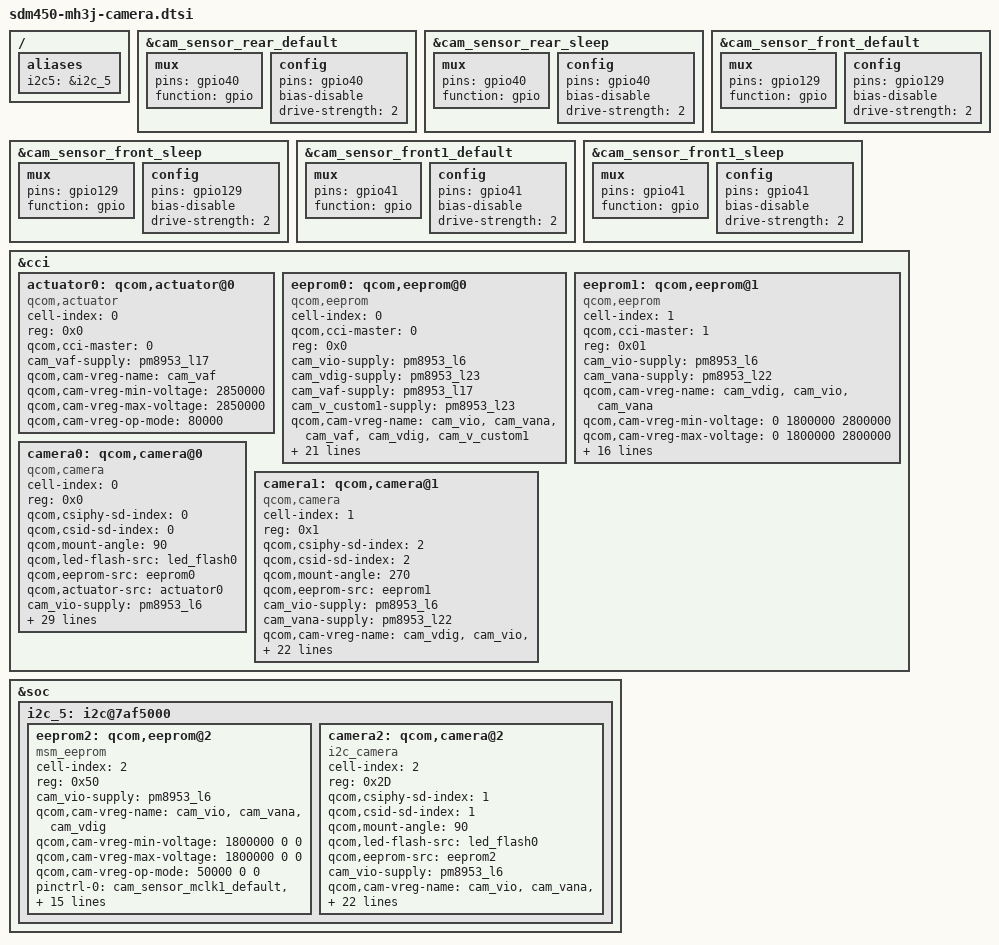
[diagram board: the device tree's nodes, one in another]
/*
 * Copyright (c) 2018, The Linux Foundation. All rights reserved.
 *
 * This program is free software; you can redistribute it and/or modify
 * it under the terms of the GNU General Public License version 2 and
 * only version 2 as published by the Free Software Foundation.
 *
 * This program is distributed in the hope that it will be useful,
 * but WITHOUT ANY WARRANTY; without even the implied warranty of
 * MERCHANTABILITY or FITNESS FOR A PARTICULAR PURPOSE.  See the
 * GNU General Public License for more details.
 */

#include "../sdm450-mh3j_common/sdm450-mh3j_common-camera.dtsi"
//#include "../../../qcom/msm8953-camera-sensor-mtp.dtsi"

/* PIN settings */
&cam_sensor_rear_default{
	/* RESET */
	mux {
		pins = "gpio40";
		function = "gpio";
	};

	config {
		pins = "gpio40";
		bias-disable; /* No PULL */
		drive-strength = <2>; /* 2 MA */
	};
};

&cam_sensor_rear_sleep{
	/* RESET */
	mux {
		pins = "gpio40";
		function = "gpio";
	};

	config {
		pins = "gpio40";
		bias-disable; /* No PULL */
		drive-strength = <2>; /* 2 MA */
	};
};

&cam_sensor_front_default{
	/* RESET */
	mux {
		pins = "gpio129";
		function = "gpio";
	};

	config {
		pins = "gpio129";
		bias-disable; /* No PULL */
		drive-strength = <2>; /* 2 MA */
	};
};

&cam_sensor_front_sleep{
	/* RESET */
	mux {
		pins = "gpio129";
		function = "gpio";
	};

	config {
		pins = "gpio129";
		bias-disable; /* No PULL */
		drive-strength = <2>; /* 2 MA */
	};
};

&cam_sensor_front1_default{
	/* RESET */
	mux {
		pins = "gpio41";
		function = "gpio";
	};

	config {
		pins = "gpio41";
		bias-disable; /* No PULL */
		drive-strength = <2>; /* 2 MA */
	};
};

&cam_sensor_front1_sleep{
	/* RESET */
	mux {
		pins = "gpio41";
		function = "gpio";
	};

	config {
		pins = "gpio41";
		bias-disable; /* No PULL */
		drive-strength = <2>; /* 2 MA */
	};
};

&cci {
	actuator0: qcom,actuator@0 {
		cell-index = <0>;
		reg = <0x0>;
		compatible = "qcom,actuator";
		qcom,cci-master = <0>;
		cam_vaf-supply = <&pm8953_l17>;
		qcom,cam-vreg-name = "cam_vaf";
		qcom,cam-vreg-min-voltage = <2850000>;
		qcom,cam-vreg-max-voltage = <2850000>;
		qcom,cam-vreg-op-mode = <80000>;
	};

	eeprom0: qcom,eeprom@0 {
		cell-index = <0>;
		compatible = "qcom,eeprom";
		qcom,cci-master = <0>;
		reg = <0x0>;
		cam_vio-supply = <&pm8953_l6>;
		cam_vdig-supply = <&pm8953_l23>;
		cam_vaf-supply = <&pm8953_l17>;
		cam_v_custom1-supply = <&pm8953_l23>;
		qcom,cam-vreg-name = "cam_vio", "cam_vana", "cam_vaf",
						"cam_vdig", "cam_v_custom1";
		qcom,cam-vreg-min-voltage = <1800000 0 2850000 1200000 1200000>;
		qcom,cam-vreg-max-voltage = <1800000 0 2850000 1200000 1200000>;
		qcom,cam-vreg-op-mode = <50000 0 100000 200000 200000>;
		pinctrl-names = "cam_default", "cam_suspend";
		pinctrl-0 = <&cam_sensor_mclk0_default
				&cam_sensor_rear_default>;
		pinctrl-1 = <&cam_sensor_mclk0_sleep &cam_sensor_rear_sleep>;
		gpios = <&tlmm 26 0>,
			<&tlmm 40 0>,
			<&tlmm 39 0>;

		qcom,gpio-no-mux = <0>;
		qcom,gpio-reset = <1>;
		qcom,gpio-vana = <2>;

		qcom,gpio-req-tbl-num = <0 1 2>;
		qcom,gpio-req-tbl-flags = <1 0 0>;
		qcom,gpio-req-tbl-label = "CAMIF_MCLK0",
			"CAM_RESET0",
			"CAM_AVDD";

		status = "ok";
		clocks = <&clock_gcc clk_mclk0_clk_src>,
				<&clock_gcc clk_gcc_camss_mclk0_clk>;
		clock-names = "cam_src_clk", "cam_clk";
		qcom,clock-rates = <24000000 0>;
	};

	eeprom1: qcom,eeprom@1 {
		cell-index = <1>;
		compatible = "qcom,eeprom";
		qcom,cci-master = <1>;
		reg = <0x01>;
		cam_vio-supply = <&pm8953_l6>;
		cam_vana-supply = <&pm8953_l22>;
		qcom,cam-vreg-name = "cam_vdig", "cam_vio", "cam_vana";

		qcom,cam-vreg-min-voltage = <0 1800000 2800000>;
		qcom,cam-vreg-max-voltage = <0 1800000 2800000>;
		qcom,cam-vreg-op-mode = <0 50000 42000>;

		pinctrl-names = "cam_default", "cam_suspend";
		pinctrl-0 = <&cam_sensor_mclk2_default
				&cam_sensor_front_default>;
		pinctrl-1 = <&cam_sensor_mclk2_sleep
				&cam_sensor_front_sleep>;
		gpios = <&tlmm 28 0>,
	               <&tlmm 129 0>,
		        <&tlmm 131 0>;

		qcom,gpio-no-mux = <0>;
		qcom,gpio-reset = <1>;
		qcom,gpio-vdig = <2>;
		qcom,gpio-req-tbl-num = <0 1 2>;
		qcom,gpio-req-tbl-flags = <1 0 0>;
		qcom,gpio-req-tbl-label = "CAMIF_MCLK2",
					  "CAM_RESET2",
					  "CAM_DVDD";

		status = "ok";
		clocks = <&clock_gcc clk_mclk2_clk_src>,
				<&clock_gcc clk_gcc_camss_mclk2_clk>;
		clock-names = "cam_src_clk", "cam_clk";
		qcom,clock-rates = <24000000 0>;

	};

	camera0: qcom,camera@0 {
		cell-index = <0>;
		compatible = "qcom,camera";
		reg = <0x0>;
		qcom,csiphy-sd-index = <0>;
		qcom,csid-sd-index = <0>;
		qcom,mount-angle = <90>;
		qcom,led-flash-src = <&led_flash0>;
		qcom,eeprom-src = <&eeprom0>;
		qcom,actuator-src = <&actuator0>;
		cam_vio-supply = <&pm8953_l6>;
		cam_vdig-supply = <&pm8953_l23>;
		cam_vaf-supply = <&pm8953_l17>;
		cam_v_custom1-supply = <&pm8953_l23>;
		qcom,cam-vreg-name = "cam_vio", "cam_vana", "cam_vaf",
						"cam_vdig", "cam_v_custom1";
		qcom,cam-vreg-min-voltage = <1800000 0 2850000 1200000 1200000>;
		qcom,cam-vreg-max-voltage = <1800000 0 2850000 1200000 1200000>;
		qcom,cam-vreg-op-mode = <50000 0 100000 200000 200000>;
		pinctrl-names = "cam_default", "cam_suspend";
		pinctrl-0 = <&cam_sensor_mclk0_default
				&cam_sensor_rear_default>;
		pinctrl-1 = <&cam_sensor_mclk0_sleep &cam_sensor_rear_sleep>;
		gpios = <&tlmm 26 0>,
			<&tlmm 40 0>,
			<&tlmm 39 0>;

		qcom,gpio-no-mux = <0>;
		qcom,gpio-reset = <1>;
		qcom,gpio-vana = <2>;

		qcom,gpio-req-tbl-num = <0 1 2>;
		qcom,gpio-req-tbl-flags = <1 0 0>;
		qcom,gpio-req-tbl-label = "CAMIF_MCLK0",
			"CAM_RESET0",
			"CAM_AVDD";

		qcom,sensor-position = <0>;
		qcom,sensor-mode = <0>;
		qcom,cci-master = <0>;
		status = "ok";
		clocks = <&clock_gcc clk_mclk0_clk_src>,
				<&clock_gcc clk_gcc_camss_mclk0_clk>;
		clock-names = "cam_src_clk", "cam_clk";
		qcom,clock-rates = <24000000 0>;
	};

	camera1: qcom,camera@1 {
		cell-index = <1>;
		compatible = "qcom,camera";
		reg = <0x1>;
		qcom,csiphy-sd-index = <2>;
		qcom,csid-sd-index = <2>;
		qcom,mount-angle = <270>;
		qcom,eeprom-src = <&eeprom1>;
		cam_vio-supply = <&pm8953_l6>;
		cam_vana-supply = <&pm8953_l22>;
		qcom,cam-vreg-name = "cam_vdig", "cam_vio", "cam_vana";

		qcom,cam-vreg-min-voltage = <0 1800000 2800000>;
		qcom,cam-vreg-max-voltage = <0 1800000 2800000>;
		qcom,cam-vreg-op-mode = <0 50000 42000>;

		pinctrl-names = "cam_default", "cam_suspend";
		pinctrl-0 = <&cam_sensor_mclk2_default
				&cam_sensor_front_default>;
		pinctrl-1 = <&cam_sensor_mclk2_sleep
				&cam_sensor_front_sleep>;
		gpios = <&tlmm 28 0>,
	               <&tlmm 129 0>,
		        <&tlmm 131 0>;

		qcom,gpio-no-mux = <0>;
		qcom,gpio-reset = <1>;
		qcom,gpio-vdig = <2>;
		qcom,gpio-req-tbl-num = <0 1 2>;
		qcom,gpio-req-tbl-flags = <1 0 0>;
		qcom,gpio-req-tbl-label = "CAMIF_MCLK2",
					  "CAM_RESET2",
					  "CAM_DVDD";

		qcom,sensor-position = <1>;
		qcom,sensor-mode = <0>;
		qcom,cci-master = <1>;
		status = "ok";
		clocks = <&clock_gcc clk_mclk2_clk_src>,
			<&clock_gcc clk_gcc_camss_mclk2_clk>;
		clock-names = "cam_src_clk", "cam_clk";
		qcom,clock-rates = <24000000 0>;
	};
};

/*W13M Rear Camera*/
/{
	aliases {
		i2c5 = &i2c_5;
	};
};

&soc{
	i2c_5: i2c@7af5000 { /* BLSP2 QUP1 */
		status = "okay";
	};
};

&i2c_5 {
	eeprom2: qcom,eeprom@2 {
		cell-index = <2>;
		compatible = "msm_eeprom";
		reg = <0x50>;
		cam_vio-supply = <&pm8953_l6>;
		qcom,cam-vreg-name = "cam_vio", "cam_vana", "cam_vdig";
		qcom,cam-vreg-min-voltage = <1800000 0 0>;
		qcom,cam-vreg-max-voltage = <1800000 0 0>;
		qcom,cam-vreg-op-mode = <50000 0 0>;
		
		pinctrl-names = "cam_default", "cam_suspend";
		pinctrl-0 = <&cam_sensor_mclk1_default
				&cam_sensor_front1_default>;
		pinctrl-1 = <&cam_sensor_mclk1_sleep &cam_sensor_front1_sleep>;
		gpios = <&tlmm 27 0>,
			<&tlmm 41 0>,
			<&tlmm 36 0>,
			<&tlmm 128 0>;

		qcom,gpio-no-mux = <0>;
		qcom,gpio-reset = <1>;
		qcom,gpio-vana = <2>;
		qcom,gpio-vdig = <3>;

		qcom,gpio-req-tbl-num = <0 1 2 3>;
		qcom,gpio-req-tbl-flags = <1 0 0 0>;
		qcom,gpio-req-tbl-label = "CAMIF_MCLK1",
			"CAM_RESET1",
			"CAM_AVDD",
			"CAM_DVDD";
			
		status = "ok";
		clocks = <&clock_gcc clk_mclk1_clk_src>,
				<&clock_gcc clk_gcc_camss_mclk1_clk>;
		clock-names = "cam_src_clk", "cam_clk";
		qcom,clock-rates = <24000000 0>;
	};

	camera2: qcom,camera@2 {
		cell-index = <2>;
		compatible = "i2c_camera";
		reg = <0x2D>;
		qcom,csiphy-sd-index = <1>;
		qcom,csid-sd-index = <1>;
		qcom,mount-angle = <90>;
		qcom,led-flash-src = <&led_flash0>;
		qcom,eeprom-src = <&eeprom2>;
		cam_vio-supply = <&pm8953_l6>;
		qcom,cam-vreg-name = "cam_vio", "cam_vana", "cam_vdig";
		qcom,cam-vreg-min-voltage = <1800000 0 0>;
		qcom,cam-vreg-max-voltage = <1800000 0 0>;
		qcom,cam-vreg-op-mode = <50000 0 0>;
		pinctrl-names = "cam_default", "cam_suspend";
		pinctrl-0 = <&cam_sensor_mclk1_default
				&cam_sensor_front1_default>;
		pinctrl-1 = <&cam_sensor_mclk1_sleep &cam_sensor_front1_sleep>;
		gpios = <&tlmm 27 0>,
			<&tlmm 41 0>,
			<&tlmm 36 0>,
			<&tlmm 128 0>;

		qcom,gpio-no-mux = <0>;
		qcom,gpio-reset = <1>;
		qcom,gpio-vana = <2>;
		qcom,gpio-vdig = <3>;

		qcom,gpio-req-tbl-num = <0 1 2 3>;
		qcom,gpio-req-tbl-flags = <1 0 0 0>;
		qcom,gpio-req-tbl-label = "CAMIF_MCLK1",
			"CAM_RESET1",
			"CAM_AVDD",
			"CAM_DVDD";

		qcom,sensor-position = <0>;
		qcom,sensor-mode = <0>;
		status = "ok";
		clocks = <&clock_gcc clk_mclk1_clk_src>,
				<&clock_gcc clk_gcc_camss_mclk1_clk>;
		clock-names = "cam_src_clk", "cam_clk";
		qcom,clock-rates = <24000000 0>;
	};
};
